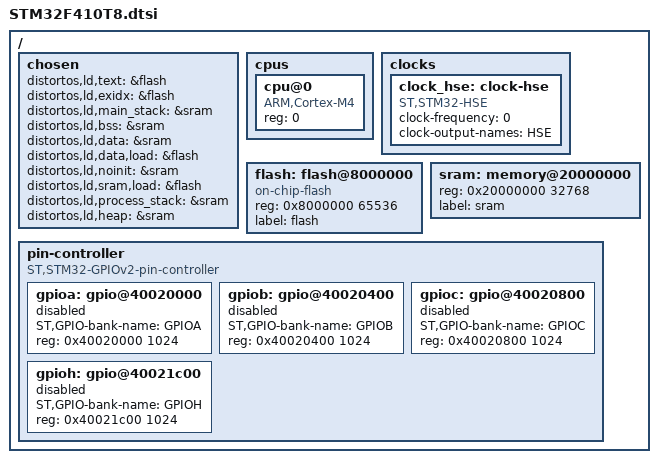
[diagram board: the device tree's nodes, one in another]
/**
 * \file
 * \brief Devicetree fragment for STM32F410T8
 *
 * \author Copyright (C) 2014-2017 Kamil Szczygiel http://www.distortec.com http://www.freddiechopin.info
 *
 * \par License
 * This Source Code Form is subject to the terms of the Mozilla Public License, v. 2.0. If a copy of the MPL was not
 * distributed with this file, You can obtain one at http://mozilla.org/MPL/2.0/.
 *
 * \warning
 * Automatically generated file - do not edit!
 */

#include "ARMv7-M.dtsi"

/ {
	chosen {
		distortos,ld,text = &flash;
		distortos,ld,exidx = &flash;
		distortos,ld,main_stack = &sram;
		distortos,ld,bss = &sram;
		distortos,ld,data = &sram;
		distortos,ld,data,load = &flash;
		distortos,ld,noinit = &sram;
		distortos,ld,sram,load = &flash;
		distortos,ld,process_stack = &sram;
		distortos,ld,heap = &sram;
	};

	cpus {
		#address-cells = <1>;
		#size-cells = <0>;

		cpu@0 {
			compatible = "ARM,Cortex-M4", "ARM,ARMv7-M";
			device_type = "cpu";
			reg = <0>;
		};
	};

	clocks {
		clock_hse: clock-hse {
			#clock-cells = <0>;
			compatible = "ST,STM32-HSE", "fixed-clock";
			clock-frequency = <0>;
			clock-output-names = "HSE";
		};
	};

	flash: flash@8000000 {
		compatible = "on-chip-flash";
		reg = <0x8000000 65536>;
		label = "flash";
	};

	sram: memory@20000000 {
		device_type = "memory";
		reg = <0x20000000 32768>;
		label = "sram";
	};

	pin-controller {
		compatible = "ST,STM32-GPIOv2-pin-controller";
		ranges;
	};

	pin-controller {
		gpioa: gpio@40020000 {
			ST,GPIO-bank-name = "GPIOA";
			#gpio-cells = <2>;
			reg = <0x40020000 1024>;
			status = "disabled";
		};
	};

	pin-controller {
		gpiob: gpio@40020400 {
			ST,GPIO-bank-name = "GPIOB";
			#gpio-cells = <2>;
			reg = <0x40020400 1024>;
			status = "disabled";
		};
	};

	pin-controller {
		gpioc: gpio@40020800 {
			ST,GPIO-bank-name = "GPIOC";
			#gpio-cells = <2>;
			reg = <0x40020800 1024>;
			status = "disabled";
		};
	};

	pin-controller {
		gpioh: gpio@40021c00 {
			ST,GPIO-bank-name = "GPIOH";
			#gpio-cells = <2>;
			reg = <0x40021c00 1024>;
			status = "disabled";
		};
	};
};
